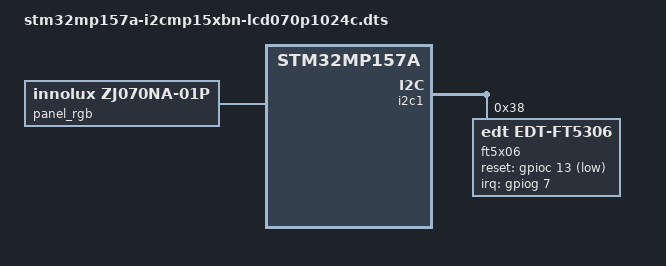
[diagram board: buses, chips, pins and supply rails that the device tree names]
// SPDX-License-Identifier: (GPL-2.0+ OR BSD-3-Clause)
/*
 * Copyright (C) i2SOM 2018 - All Rights Reserved
 * Author: Steve Chen <steve.chen@i2som.tech>.
 */

/dts-v1/;

#include "stm32mp157a-i2cmp15xbn.dts"

&panel_rgb {
	compatible = "innolux,zj070na-01p";
};

&i2c1 {
/*
	tsc2007: tsc2007@48 {
		compatible = "ti,tsc2007";
		reg = <0x48>;
		interrupt-parent = <&gpioi>;
		interrupts = <8 IRQ_TYPE_EDGE_FALLING>;
		interrupt-controller;
		gpios = <&gpioi 8 GPIO_ACTIVE_LOW>;
		ti,x-plate-ohms = <660>;
	};
*/
	ft5x06: ft5x06@38 {
		compatible = "edt,edt-ft5306";
		reg = <0x38>;
		interrupts = <7 IRQ_TYPE_EDGE_FALLING>;
		interrupt-parent = <&gpiog>;
		interrupt-controller;
		reset-gpios = <&gpioc 13 GPIO_ACTIVE_LOW>;
		status = "okay";
	};
};

